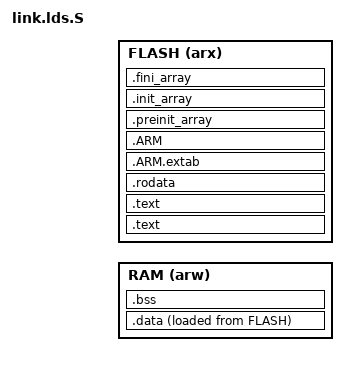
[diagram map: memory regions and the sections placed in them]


/* Entry Point */
ENTRY(Reset_Handler)

/* Specify the memory areas */
MEMORY
{
  RAM (arw)      : ORIGIN = CONFIG_SYS_DATA_ADDR, LENGTH = CONFIG_SYS_DATA_SIZE
  FLASH (arx)      : ORIGIN = CONFIG_SYS_TEXT_ADDR + CONFIG_BOOTSTRAP_TEXT_SIZE + CONFIG_DTBO_TEXT_SIZE, LENGTH = CONFIG_KNL_TEXT_SIZE
}

/* Define output sections */
SECTIONS
{
  . = ORIGIN(FLASH);
  .text :
  {
      KEEP(*(.isr_vector))

      *(.text)
      *(.text*)
      *(.rodata*)
  } > FLASH

  /* The program code and other data goes into FLASH */
  .text :
  {
    . = ALIGN(4);
    *(.text)           /* .text sections (code) */
    *(.text*)          /* .text* sections (code) */
    *(.glue_7)         /* glue arm to thumb code */
    *(.glue_7t)        /* glue thumb to arm code */
    *(.eh_frame)

    KEEP (*(.init))
    KEEP (*(.fini))

    . = ALIGN(4);
    _etext = .;        /* define a global symbols at end of code */

  } >FLASH

  /* Constant data goes into FLASH */
  .rodata :
  {
    . = ALIGN(4);
    *(.rodata)         /* .rodata sections (constants, strings, etc.) */
    *(.rodata*)        /* .rodata* sections (constants, strings, etc.) */
    . = ALIGN(4);
  } >FLASH

  .ARM.extab   : { *(.ARM.extab* .gnu.linkonce.armextab.*) } >FLASH
  .ARM : {
    __exidx_start = .;
    *(.ARM.exidx*)
    __exidx_end = .;
  } >FLASH

  .preinit_array     :
  {
    PROVIDE_HIDDEN (__preinit_array_start = .);
    KEEP (*(.preinit_array*))
    PROVIDE_HIDDEN (__preinit_array_end = .);
  } >FLASH
  .init_array :
  {
    PROVIDE_HIDDEN (__init_array_start = .);
    KEEP (*(SORT(.init_array.*)))
    KEEP (*(.init_array*))
    PROVIDE_HIDDEN (__init_array_end = .);
  } >FLASH
  .fini_array :
  {
    PROVIDE_HIDDEN (__fini_array_start = .);
    KEEP (*(SORT(.fini_array.*)))
    KEEP (*(.fini_array*))
    PROVIDE_HIDDEN (__fini_array_end = .);
  } >FLASH

  /* used by the startup to initialize data */
  _sidata = LOADADDR(.data);

  /* Initialized data sections goes into RAM, load LMA copy after code */
  .data : 
  {
    . = ALIGN(4);
    _sdata = .;        /* create a global symbol at data start */
    *(.data)           /* .data sections */
    *(.data*)          /* .data* sections */

    . = ALIGN(0x4);
		_pre_cpu_data_start = .;
		KEEP (*(.data.per_cpu))
		_pre_cpu_data_end = .;

    . = ALIGN(4);
    _edata = .;        /* define a global symbol at data end */
  } >RAM AT> FLASH


  /* Uninitialized data section */
  . = ALIGN(4);
  .bss :
  {
    /* This is used by the startup in order to initialize the .bss secion */
    _sbss = .;         /* define a global symbol at bss start */
    __bss_start__ = _sbss;
    *(.bss)
    *(.bss*)
    *(COMMON)

    . = ALIGN(4);
    _ebss = .;         /* define a global symbol at bss end */
    __bss_end__ = _ebss;
  } >RAM
  .ARM.attributes 0 : { *(.ARM.attributes) }
}


